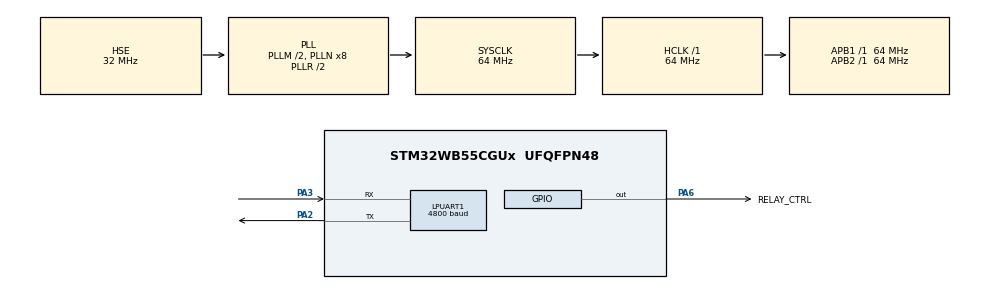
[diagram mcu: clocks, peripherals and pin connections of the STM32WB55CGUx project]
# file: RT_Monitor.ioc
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LPUART1.BaudRate=4800
Mcu.Family=STM32WB
Mcu.Name=STM32WB55CGUx
Mcu.Package=UFQFPN48
NVIC.HSEM_IRQn=true\:0\:0\:false\:false\:true\:false\:true\:true
NVIC.IPCC_C1_RX_IRQn=true\:0\:0\:true\:false\:true\:true\:true\:true
NVIC.IPCC_C1_TX_IRQn=true\:0\:0\:true\:false\:true\:true\:true\:true
NVIC.LPUART1_IRQn=true\:0\:0\:false\:false\:true\:true\:true\:true
NVIC.PriorityGroup=NVIC_PRIORITYGROUP_4
NVIC.RTC_WKUP_IRQn=true\:0\:0\:true\:false\:true\:true\:true\:true
NVIC.TIM2_IRQn=true\:0\:0\:false\:false\:true\:true\:true\:true
OSC_IN.Mode=HSE-External-Oscillator
OSC_IN.Signal=RCC_OSC_IN
OSC_OUT.Mode=HSE-External-Oscillator
OSC_OUT.Signal=RCC_OSC_OUT
PA13.Mode=Serial_Wire
PA13.Signal=SYS_JTMS-SWDIO
PA14.Mode=Serial_Wire
PA14.Signal=SYS_JTCK-SWCLK
PA2.Mode=Asynchronous
PA2.Signal=LPUART1_TX
PA3.Mode=Asynchronous
PA3.Signal=LPUART1_RX
PA6.GPIO_Label=RELAY_CTRL
PA6.Signal=GPIO_Output
PC14-OSC32_IN.Mode=LSE-External-Oscillator
PC14-OSC32_IN.Signal=RCC_OSC32_IN
PC15-OSC32_OUT.Mode=LSE-External-Oscillator
PC15-OSC32_OUT.Signal=RCC_OSC32_OUT
ProjectManager.HeapSize=0x200
ProjectManager.StackSize=0x400
ProjectManager.TargetToolchain=STM32CubeIDE
RCC.ADCFreq_Value=64000000
RCC.AHB2CLKDivider=RCC_SYSCLK_DIV2
RCC.AHB3CLKDivider=RCC_SYSCLK_DIV2
RCC.AHBFreq_Value=64000000
RCC.APB1Freq_Value=64000000
RCC.APB1TimFreq_Value=64000000
RCC.APB2Freq_Value=64000000
RCC.APB2TimFreq_Value=64000000
RCC.APB3Freq_Value=16000000
RCC.CortexFreq_Value=64000000
RCC.HCLKFreq_Value=64000000
RCC.HSE_VALUE=32000000
RCC.HSI48_VALUE=48000000
RCC.HSI_VALUE=16000000
RCC.LPUART1CLockSelection=RCC_LPUART1CLKSOURCE_HSI
RCC.PLLM=RCC_PLLM_DIV2
RCC.PLLSourceVirtual=RCC_PLLSOURCE_HSE
RCC.SYSCLKFreq_VALUE=64000000
RCC.SYSCLKSource=RCC_SYSCLKSOURCE_PLLCLK
RCC.USBFreq_Value=64000000
RCC.VCOOutputFreq_Value=128000000
RF1.Mode=RF1_Activate
RF1.Signal=RF_RF1
RTC.Format=RTC_FORMAT_BIN
RTC.Hours=6
RTC.WakeUpCounter-WakeUp=0
STM32_WPAN.AD_TYPE_COMPLETE_LOCAL_NAME=STM32_BLE
STM32_WPAN.AD_TYPE_COMPLETE_LOCAL_NAME_LENGTH=10
STM32_WPAN.BT_SIG_HEART_RATE_SENSOR=Disabled
STM32_WPAN.CFG_LSCLK_LSE=0
STM32_WPAN.CFG_RTCCLK_DIVIDER_CONF=\ 16
STM32_WPAN.CFG_TX_POWER=(0x1F) /* 6dBm */
STM32_WPAN.CUSTOM_P2P_SERVER=Disabled
STM32_WPAN.CUSTOM_TEMPLATE=Enabled
STM32_WPAN.INCLUDE_AD_TYPE_COMPLETE_LOCAL_NAME=1
STM32_WPAN.NUMBER_OF_SERVICES=1
STM32_WPAN.SERVICE1_CHAR1_GATT_NOTIFY_READ_REQ_AND_WAIT_FOR_APPL_RESP=\ 
STM32_WPAN.SERVICE1_CHAR1_GATT_NOTIFY_WRITE_REQ_AND_WAIT_FOR_APPL_RESP=\ 
STM32_WPAN.SERVICE1_CHAR1_LONG_NAME=relayControl
STM32_WPAN.SERVICE1_CHAR1_PROP_WRITE=CHAR_PROP_WRITE
STM32_WPAN.SERVICE1_CHAR1_SHORT_NAME=relayControl
STM32_WPAN.SERVICE1_CHAR1_UUID=00 00
STM32_WPAN.SERVICE1_CHAR1_UUID_128_INPUT_TYPE=0
STM32_WPAN.SERVICE1_CHAR1_VALUE_LENGTH=5
STM32_WPAN.SERVICE1_CHAR2_GATT_NOTIFY_ATTRIBUTE_WRITE=\ 
STM32_WPAN.SERVICE1_CHAR2_GATT_NOTIFY_READ_REQ_AND_WAIT_FOR_APPL_RESP=\ 
STM32_WPAN.SERVICE1_CHAR2_GATT_NOTIFY_WRITE_REQ_AND_WAIT_FOR_APPL_RESP=\ 
STM32_WPAN.SERVICE1_CHAR2_LONG_NAME=myCharNotify
STM32_WPAN.SERVICE1_CHAR2_PROP_NOTIFY=CHAR_PROP_NOTIFY
STM32_WPAN.SERVICE1_CHAR2_SHORT_NAME=myCharNotify
STM32_WPAN.SERVICE1_CHAR2_UUID=00 01
STM32_WPAN.SERVICE1_CHAR2_VALUE_LENGTH=100
STM32_WPAN.SERVICE1_CHAR3_GATT_NOTIFY_READ_REQ_AND_WAIT_FOR_APPL_RESP=\ 
STM32_WPAN.SERVICE1_CHAR3_GATT_NOTIFY_WRITE_REQ_AND_WAIT_FOR_APPL_RESP=\ 
STM32_WPAN.SERVICE1_CHAR3_LONG_NAME=set_device_name
STM32_WPAN.SERVICE1_CHAR3_PROP_WRITE=CHAR_PROP_WRITE
STM32_WPAN.SERVICE1_CHAR3_SHORT_NAME=set_device_name
STM32_WPAN.SERVICE1_CHAR3_UUID=00 02
STM32_WPAN.SERVICE1_CHAR3_VALUE_LENGTH=9
STM32_WPAN.SERVICE1_CHAR4_GATT_NOTIFY_READ_REQ_AND_WAIT_FOR_APPL_RESP=\ 
STM32_WPAN.SERVICE1_CHAR4_GATT_NOTIFY_WRITE_REQ_AND_WAIT_FOR_APPL_RESP=\ 
STM32_WPAN.SERVICE1_CHAR4_LONG_NAME=set_date_and_time
STM32_WPAN.SERVICE1_CHAR4_PROP_WRITE=CHAR_PROP_WRITE
STM32_WPAN.SERVICE1_CHAR4_SHORT_NAME=set_date_and_time
STM32_WPAN.SERVICE1_CHAR4_UUID=00 03
STM32_WPAN.SERVICE1_CHAR4_VALUE_LENGTH=25
STM32_WPAN.SERVICE1_LONG_NAME=bpService
STM32_WPAN.SERVICE1_NUMBER_OF_CHARACTERISTICS=4
STM32_WPAN.SERVICE1_SHORT_NAME=bpService
STM32_WPAN.SERVICE1_UUID=00 00
STM32_WPAN.SERVICE1_UUID_128_INPUT_TYPE=0
STM32_WPAN.SERVICE2_CHAR1_LONG_NAME=TEST
STM32_WPAN.SERVICE2_CHAR1_PROP_READ=CHAR_PROP_READ
STM32_WPAN.SERVICE2_CHAR1_SHORT_NAME=TEST
STM32_WPAN.SERVICE2_LONG_NAME=bpService1
STM32_WPAN.SERVICE2_SHORT_NAME=bpService1
TIM2.Period=1000-1
TIM2.Prescaler=64000-1
VP_HSEM_VS_HSEM.Mode=HSEM_Activate
VP_IPCC_VS_IPCC.Mode=IPCC_Activate
VP_MEMORYMAP_VS_MEMORYMAP.Mode=CurAppReg
VP_RTC_VS_RTC_Activate.Mode=RTC_Enabled
VP_RTC_VS_RTC_Calendar.Mode=RTC_Calendar
VP_RTC_VS_RTC_WakeUp_intern.Mode=WakeUp
VP_SEQUENCER_VS_SEQUENCER.Mode=SEQUENCER_Enabled
VP_STM32_WPAN_VS_BLE_HOST.Mode=STM32_WPAN_Enabled
VP_TIM2_VS_ClockSourceINT.Mode=Internal
VP_TINY_LPM_VS_TINY_LPM.Mode=TINY_LPM_Enabled
board=custom

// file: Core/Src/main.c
/* USER CODE BEGIN Header */
/**
  ******************************************************************************
  * @file           : main.c
  * @brief          : Main program body
  ******************************************************************************
  * @attention
  *
  * Copyright (c) 2025 STMicroelectronics.
  * All rights reserved.
  *
  * This software is licensed under terms that can be found in the LICENSE file
  * in the root directory of this software component.
  * If no LICENSE file comes with this software, it is provided AS-IS.
  *
  ******************************************************************************
  */
/* USER CODE END Header */
#include "main.h"

/* USER CODE BEGIN Includes */
#include <stdbool.h>
/* USER CODE END Includes */

/* USER CODE BEGIN PTD */
RTC_TimeTypeDef sTime;
RTC_DateTypeDef sDate;
/* USER CODE END PTD */

/* USER CODE BEGIN PD */
#define RX_BUFFER_SIZE 4
#define TX_BUFFER_SIZE 2
#define BL0942_VREF 1.218
#define BL0942_V_RMS_LBS 73989
#define BL0942_V_R1  2340000
#define BL0942_V_R2  510
#define BL0942_I_RMS_LBS 305978
#define BL0942_CF_CNT (1638.4 * 256 * BL0942_VREF * BL0942_VREF * BL0942_V_R1) / (3600000.0* 3537.0 * (BL0942_I_R1 * 1000.0 / BL0942_I_Rt) * BL0942_V_R2 * 1000.0)
/* USER CODE END PD */

IPCC_HandleTypeDef hipcc;

UART_HandleTypeDef hlpuart1;

RTC_HandleTypeDef hrtc;

TIM_HandleTypeDef htim2;

/* USER CODE BEGIN PV */
uint8_t rxBuffer[RX_BUFFER_SIZE];
uint8_t rxBuffer1[RX_BUFFER_SIZE];
uint8_t txBuffer[2];
float BL0942_I_R1  = 1 ;
float BL0942_I_Rt =888 ;
int tick = 0;
bool flag_Update = false;
float voltage;
float current;
float power;
uint32_t get_reg_data;
uint32_t I_RMS_ADC = 0;
uint32_t V_RMS_ADC = 0;
uint32_t W_RMS_ADC = 0;
extern bool isMeasuring;
/* USER CODE END PV */

void SystemClock_Config(void);
void PeriphCommonClock_Config(void);
static void MX_GPIO_Init(void);
static void MX_IPCC_Init(void);
static void MX_RTC_Init(void);
static void MX_LPUART1_UART_Init(void);
static void MX_TIM2_Init(void);
static void MX_RF_Init(void);

/* USER CODE BEGIN 0 */
void HAL_UART_RxCpltCallback(UART_HandleTypeDef *huart) {
	if(huart->Instance == LPUART1)
	{
	  get_reg_data = (int32_t)((uint8_t)rxBuffer[2] << 16 |
												 (uint8_t)rxBuffer[1] << 8  |
												 (uint8_t)rxBuffer[0]);

		if (get_reg_data != 0)
		{
			W_RMS_ADC = get_reg_data;
		}
		else
		{
			if(get_reg_data ==0)
			{
				W_RMS_ADC = 0;
			}
			get_reg_data = W_RMS_ADC;
		}
		power = (get_reg_data * BL0942_VREF * BL0942_VREF * BL0942_V_R1) / (3537.0 * (BL0942_I_R1 * 1000.0 / BL0942_I_Rt) * BL0942_V_R2 * 1000.0);

		HAL_UART_Receive_IT(&hlpuart1, rxBuffer, RX_BUFFER_SIZE);
	}
}
/* USER CODE END 0 */

int main(void)
{

  /* MCU Configuration--------------------------------------------------------*/

  /* Reset of all peripherals, Initializes the Flash interface and the Systick. */
  HAL_Init();
  /* Config code for STM32_WPAN (HSE Tuning must be done before system clock configuration) */
  MX_APPE_Config();

  /* Configure the system clock */
  SystemClock_Config();

  /* Configure the peripherals common clocks */
  PeriphCommonClock_Config();

  /* IPCC initialisation */
  MX_IPCC_Init();

  /* Initialize all configured peripherals */
  MX_GPIO_Init();
  MX_RTC_Init();
  MX_LPUART1_UART_Init();
  MX_TIM2_Init();
  MX_RF_Init();
  /* USER CODE BEGIN 2 */
  HAL_UART_Receive_IT(&hlpuart1, rxBuffer, RX_BUFFER_SIZE);
  HAL_TIM_Base_Start_IT(&htim2);
  /* USER CODE END 2 */

  /* Init code for STM32_WPAN */
  MX_APPE_Init();

  /* Infinite loop */
  while (1)
  {
    MX_APPE_Process();

  }
}

void SystemClock_Config(void)
{
  RCC_OscInitTypeDef RCC_OscInitStruct = {0};
  RCC_ClkInitTypeDef RCC_ClkInitStruct = {0};

  /** Configure the main internal regulator output voltage
  */
  __HAL_PWR_VOLTAGESCALING_CONFIG(PWR_REGULATOR_VOLTAGE_SCALE1);

  /** Initializes the RCC Oscillators according to the specified parameters
  * in the RCC_OscInitTypeDef structure.
  */
  RCC_OscInitStruct.OscillatorType = RCC_OSCILLATORTYPE_HSI|RCC_OSCILLATORTYPE_LSI1
                              |RCC_OSCILLATORTYPE_HSE;
  RCC_OscInitStruct.HSEState = RCC_HSE_ON;
  RCC_OscInitStruct.HSIState = RCC_HSI_ON;
  RCC_OscInitStruct.HSICalibrationValue = RCC_HSICALIBRATION_DEFAULT;
  RCC_OscInitStruct.LSIState = RCC_LSI_ON;
  RCC_OscInitStruct.PLL.PLLState = RCC_PLL_ON;
  RCC_OscInitStruct.PLL.PLLSource = RCC_PLLSOURCE_HSE;
  RCC_OscInitStruct.PLL.PLLM = RCC_PLLM_DIV2;
  RCC_OscInitStruct.PLL.PLLN = 8;
  RCC_OscInitStruct.PLL.PLLP = RCC_PLLP_DIV2;
  RCC_OscInitStruct.PLL.PLLR = RCC_PLLR_DIV2;
  RCC_OscInitStruct.PLL.PLLQ = RCC_PLLQ_DIV2;
  if (HAL_RCC_OscConfig(&RCC_OscInitStruct) != HAL_OK)
  {
    Error_Handler();
  }

  /** Configure the SYSCLKSource, HCLK, PCLK1 and PCLK2 clocks dividers
  */
  RCC_ClkInitStruct.ClockType = RCC_CLOCKTYPE_HCLK4|RCC_CLOCKTYPE_HCLK2
                              |RCC_CLOCKTYPE_HCLK|RCC_CLOCKTYPE_SYSCLK
                              |RCC_CLOCKTYPE_PCLK1|RCC_CLOCKTYPE_PCLK2;
  RCC_ClkInitStruct.SYSCLKSource = RCC_SYSCLKSOURCE_PLLCLK;
  RCC_ClkInitStruct.AHBCLKDivider = RCC_SYSCLK_DIV1;
  RCC_ClkInitStruct.APB1CLKDivider = RCC_HCLK_DIV1;
  RCC_ClkInitStruct.APB2CLKDivider = RCC_HCLK_DIV1;
  RCC_ClkInitStruct.AHBCLK2Divider = RCC_SYSCLK_DIV2;
  RCC_ClkInitStruct.AHBCLK4Divider = RCC_SYSCLK_DIV2;

  if (HAL_RCC_ClockConfig(&RCC_ClkInitStruct, FLASH_LATENCY_1) != HAL_OK)
  {
    Error_Handler();
  }
}

void PeriphCommonClock_Config(void)
{
  RCC_PeriphCLKInitTypeDef PeriphClkInitStruct = {0};

  /** Initializes the peripherals clock
  */
  PeriphClkInitStruct.PeriphClockSelection = RCC_PERIPHCLK_SMPS|RCC_PERIPHCLK_RFWAKEUP;
  PeriphClkInitStruct.RFWakeUpClockSelection = RCC_RFWKPCLKSOURCE_HSE_DIV1024;
  PeriphClkInitStruct.SmpsClockSelection = RCC_SMPSCLKSOURCE_HSI;
  PeriphClkInitStruct.SmpsDivSelection = RCC_SMPSCLKDIV_RANGE1;

  if (HAL_RCCEx_PeriphCLKConfig(&PeriphClkInitStruct) != HAL_OK)
  {
    Error_Handler();
  }
}

static void MX_IPCC_Init(void)
{

  hipcc.Instance = IPCC;
  if (HAL_IPCC_Init(&hipcc) != HAL_OK)
  {
    Error_Handler();
  }

}

static void MX_LPUART1_UART_Init(void)
{

  hlpuart1.Instance = LPUART1;
  hlpuart1.Init.BaudRate = 4800;
  hlpuart1.Init.WordLength = UART_WORDLENGTH_8B;
  hlpuart1.Init.StopBits = UART_STOPBITS_1;
  hlpuart1.Init.Parity = UART_PARITY_NONE;
  hlpuart1.Init.Mode = UART_MODE_TX_RX;
  hlpuart1.Init.HwFlowCtl = UART_HWCONTROL_NONE;
  hlpuart1.Init.OneBitSampling = UART_ONE_BIT_SAMPLE_DISABLE;
  hlpuart1.Init.ClockPrescaler = UART_PRESCALER_DIV1;
  hlpuart1.AdvancedInit.AdvFeatureInit = UART_ADVFEATURE_NO_INIT;
  hlpuart1.FifoMode = UART_FIFOMODE_DISABLE;
  if (HAL_UART_Init(&hlpuart1) != HAL_OK)
  {
    Error_Handler();
  }
  if (HAL_UARTEx_SetTxFifoThreshold(&hlpuart1, UART_TXFIFO_THRESHOLD_1_8) != HAL_OK)
  {
    Error_Handler();
  }
  if (HAL_UARTEx_SetRxFifoThreshold(&hlpuart1, UART_RXFIFO_THRESHOLD_1_8) != HAL_OK)
  {
    Error_Handler();
  }
  if (HAL_UARTEx_DisableFifoMode(&hlpuart1) != HAL_OK)
  {
    Error_Handler();
  }

}

static void MX_RF_Init(void)
{

}

static void MX_RTC_Init(void)
{

  RTC_TimeTypeDef sTime = {0};
  RTC_DateTypeDef sDate = {0};

  /** Initialize RTC Only
  */
  hrtc.Instance = RTC;
  hrtc.Init.HourFormat = RTC_HOURFORMAT_24;
  hrtc.Init.AsynchPrediv = CFG_RTC_ASYNCH_PRESCALER;
  hrtc.Init.SynchPrediv = CFG_RTC_SYNCH_PRESCALER;
  hrtc.Init.OutPut = RTC_OUTPUT_DISABLE;
  hrtc.Init.OutPutPolarity = RTC_OUTPUT_POLARITY_HIGH;
  hrtc.Init.OutPutType = RTC_OUTPUT_TYPE_OPENDRAIN;
  hrtc.Init.OutPutRemap = RTC_OUTPUT_REMAP_NONE;
  if (HAL_RTC_Init(&hrtc) != HAL_OK)
  {
    Error_Handler();
  }

  /** Initialize RTC and set the Time and Date
  */
  sTime.Hours = 6;
  sTime.Minutes = 0;
  sTime.Seconds = 0;
  sTime.SubSeconds = 0x0;
  sTime.DayLightSaving = RTC_DAYLIGHTSAVING_NONE;
  sTime.StoreOperation = RTC_STOREOPERATION_RESET;
  if (HAL_RTC_SetTime(&hrtc, &sTime, RTC_FORMAT_BIN) != HAL_OK)
  {
    Error_Handler();
  }
  sDate.WeekDay = RTC_WEEKDAY_MONDAY;
  sDate.Month = RTC_MONTH_JANUARY;
  sDate.Date = 1;
  sDate.Year = 0;

  if (HAL_RTC_SetDate(&hrtc, &sDate, RTC_FORMAT_BIN) != HAL_OK)
  {
    Error_Handler();
  }

  /** Enable the WakeUp
  */
  if (HAL_RTCEx_SetWakeUpTimer_IT(&hrtc, 0, RTC_WAKEUPCLOCK_RTCCLK_DIV16) != HAL_OK)
  {
    Error_Handler();
  }

}

static void MX_TIM2_Init(void)
{

  TIM_ClockConfigTypeDef sClockSourceConfig = {0};
  TIM_MasterConfigTypeDef sMasterConfig = {0};

  htim2.Instance = TIM2;
  htim2.Init.Prescaler = 64000-1;
  htim2.Init.CounterMode = TIM_COUNTERMODE_UP;
  htim2.Init.Period = 1000-1;
  htim2.Init.ClockDivision = TIM_CLOCKDIVISION_DIV1;
  htim2.Init.AutoReloadPreload = TIM_AUTORELOAD_PRELOAD_DISABLE;
  if (HAL_TIM_Base_Init(&htim2) != HAL_OK)
  {
    Error_Handler();
  }
  sClockSourceConfig.ClockSource = TIM_CLOCKSOURCE_INTERNAL;
  if (HAL_TIM_ConfigClockSource(&htim2, &sClockSourceConfig) != HAL_OK)
  {
    Error_Handler();
  }
  sMasterConfig.MasterOutputTrigger = TIM_TRGO_RESET;
  sMasterConfig.MasterSlaveMode = TIM_MASTERSLAVEMODE_DISABLE;
  if (HAL_TIMEx_MasterConfigSynchronization(&htim2, &sMasterConfig) != HAL_OK)
  {
    Error_Handler();
  }

}

static void MX_GPIO_Init(void)
{
  GPIO_InitTypeDef GPIO_InitStruct = {0};

  /* GPIO Ports Clock Enable */
  __HAL_RCC_GPIOC_CLK_ENABLE();
  __HAL_RCC_GPIOA_CLK_ENABLE();

  /*Configure GPIO pin Output Level */
  HAL_GPIO_WritePin(RELAY_CTRL_GPIO_Port, RELAY_CTRL_Pin, GPIO_PIN_RESET);

  /*Configure GPIO pin : RELAY_CTRL_Pin */
  GPIO_InitStruct.Pin = RELAY_CTRL_Pin;
  GPIO_InitStruct.Mode = GPIO_MODE_OUTPUT_PP;
  GPIO_InitStruct.Pull = GPIO_NOPULL;
  GPIO_InitStruct.Speed = GPIO_SPEED_FREQ_LOW;
  HAL_GPIO_Init(RELAY_CTRL_GPIO_Port, &GPIO_InitStruct);

}

/* USER CODE BEGIN 4 */
void HAL_TIM_PeriodElapsedCallback(TIM_HandleTypeDef *htim)
{
	if(htim->Instance == TIM2){
		HAL_RTC_GetTime(&hrtc, &sTime, RTC_FORMAT_BIN);
		HAL_RTC_GetDate(&hrtc, &sDate, RTC_FORMAT_BIN);
		tick++;
		if (tick == 5) {
			tick = 0;
			if(isMeasuring == true)
			{
            	txBuffer[0] = 0x58;
            	txBuffer[1] = 0x06;
            	HAL_UART_Transmit(&hlpuart1, txBuffer, 2, 1000);
			}
			flag_Update = true;
		}
	}
}
/* USER CODE END 4 */

void Error_Handler(void)
{
  __disable_irq();
  while (1)
  {
  }
}
